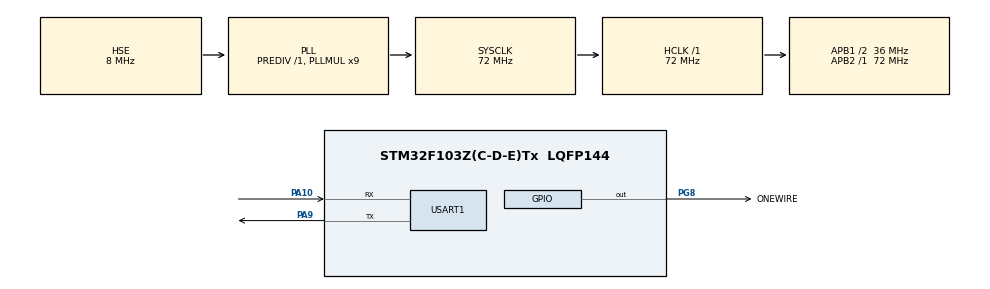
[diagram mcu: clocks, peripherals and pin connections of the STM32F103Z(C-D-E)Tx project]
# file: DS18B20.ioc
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Mcu.Family=STM32F1
Mcu.Name=STM32F103Z(C-D-E)Tx
Mcu.Package=LQFP144
NVIC.PriorityGroup=NVIC_PRIORITYGROUP_4
OSC_IN.Mode=HSE-External-Oscillator
OSC_IN.Signal=RCC_OSC_IN
OSC_OUT.Mode=HSE-External-Oscillator
OSC_OUT.Signal=RCC_OSC_OUT
PA10.Mode=Asynchronous
PA10.Signal=USART1_RX
PA9.Mode=Asynchronous
PA9.Signal=USART1_TX
PG8.GPIO_Label=ONEWIRE
PG8.Signal=GPIO_Output
ProjectManager.HeapSize=0x200
ProjectManager.StackSize=0x400
ProjectManager.TargetToolchain=MDK-ARM V5
RCC.AHBFreq_Value=72000000
RCC.APB1CLKDivider=RCC_HCLK_DIV2
RCC.APB1Freq_Value=36000000
RCC.APB1TimFreq_Value=72000000
RCC.APB2Freq_Value=72000000
RCC.APB2TimFreq_Value=72000000
RCC.HCLKFreq_Value=72000000
RCC.HSIState=RCC_HSI_ON
RCC.PLLMUL=RCC_PLL_MUL9
RCC.PLLSourceVirtual=RCC_PLLSOURCE_HSE
RCC.SYSCLKFreq_VALUE=72000000
RCC.SYSCLKSource=RCC_SYSCLKSOURCE_PLLCLK
RCC.USBFreq_Value=72000000
VP_SYS_VS_ND.Mode=No_Debug
board=DS18B20

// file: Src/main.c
/**
  ******************************************************************************
  * File Name          : main.c
  * Description        : Main program body
  ******************************************************************************
  *
  * COPYRIGHT(c) 2017 STMicroelectronics
  *
  * Redistribution and use in source and binary forms, with or without modification,
  * are permitted provided that the following conditions are met:
  *   1. Redistributions of source code must retain the above copyright notice,
  *      this list of conditions and the following disclaimer.
  *   2. Redistributions in binary form must reproduce the above copyright notice,
  *      this list of conditions and the following disclaimer in the documentation
  *      and/or other materials provided with the distribution.
  *   3. Neither the name of STMicroelectronics nor the names of its contributors
  *      may be used to endorse or promote products derived from this software
  *      without specific prior written permission.
  *
  * THIS SOFTWARE IS PROVIDED BY THE COPYRIGHT HOLDERS AND CONTRIBUTORS "AS IS"
  * AND ANY EXPRESS OR IMPLIED WARRANTIES, INCLUDING, BUT NOT LIMITED TO, THE
  * IMPLIED WARRANTIES OF MERCHANTABILITY AND FITNESS FOR A PARTICULAR PURPOSE ARE
  * DISCLAIMED. IN NO EVENT SHALL THE COPYRIGHT HOLDER OR CONTRIBUTORS BE LIABLE
  * FOR ANY DIRECT, INDIRECT, INCIDENTAL, SPECIAL, EXEMPLARY, OR CONSEQUENTIAL
  * DAMAGES (INCLUDING, BUT NOT LIMITED TO, PROCUREMENT OF SUBSTITUTE GOODS OR
  * SERVICES; LOSS OF USE, DATA, OR PROFITS; OR BUSINESS INTERRUPTION) HOWEVER
  * CAUSED AND ON ANY THEORY OF LIABILITY, WHETHER IN CONTRACT, STRICT LIABILITY,
  * OR TORT (INCLUDING NEGLIGENCE OR OTHERWISE) ARISING IN ANY WAY OUT OF THE USE
  * OF THIS SOFTWARE, EVEN IF ADVISED OF THE POSSIBILITY OF SUCH DAMAGE.
  *
  ******************************************************************************
  */
#include "main.h"
#include "stm32f1xx_hal.h"
#include "usart.h"
#include "gpio.h"

/* USER CODE BEGIN Includes */
#include "ds18b20.h"
/* USER CODE END Includes */

/* USER CODE BEGIN PV */
/* Private variables ---------------------------------------------------------*/

/* USER CODE END PV */

void SystemClock_Config(void);
void Error_Handler(void);

/* USER CODE BEGIN PFP */
/* Private function prototypes -----------------------------------------------*/

/* USER CODE END PFP */

int main(void)
{

  /* USER CODE BEGIN 1 */
  int16_t temp;
  /* USER CODE END 1 */

  /* MCU Configuration----------------------------------------------------------*/

  /* Reset of all peripherals, Initializes the Flash interface and the Systick. */
  HAL_Init();

  /* Configure the system clock */
  SystemClock_Config();

  /* Initialize all configured peripherals */
  MX_GPIO_Init();
  MX_USART1_UART_Init();

  /* USER CODE BEGIN 2 */
  printf ("DS18B20 Example\r\n");

  /* Initialize DS18B20 and chack */
  while(DS18B20_Init())
  {
    printf ("DS18B20 Check Failed! Please Check!\r\n");
    HAL_Delay(500);
  }
  temp=DS18B20_Get_Temp();
  HAL_Delay(800);
  /* USER CODE END 2 */

  /* Infinite loop */
  while (1)
  {

  /* USER CODE BEGIN 3 */
    temp = DS18B20_Get_Temp();
    printf("Temperate:  %3.1f C \r\n",temp/10.0f );
    HAL_Delay(500);
  }
  /* USER CODE END 3 */

}

/** System Clock Configuration
*/
void SystemClock_Config(void)
{

  RCC_OscInitTypeDef RCC_OscInitStruct;
  RCC_ClkInitTypeDef RCC_ClkInitStruct;

    /**Initializes the CPU, AHB and APB busses clocks
    */
  RCC_OscInitStruct.OscillatorType = RCC_OSCILLATORTYPE_HSE;
  RCC_OscInitStruct.HSEState = RCC_HSE_ON;
  RCC_OscInitStruct.HSEPredivValue = RCC_HSE_PREDIV_DIV1;
  RCC_OscInitStruct.HSIState = RCC_HSI_ON;
  RCC_OscInitStruct.PLL.PLLState = RCC_PLL_ON;
  RCC_OscInitStruct.PLL.PLLSource = RCC_PLLSOURCE_HSE;
  RCC_OscInitStruct.PLL.PLLMUL = RCC_PLL_MUL9;
  if (HAL_RCC_OscConfig(&RCC_OscInitStruct) != HAL_OK)
  {
    Error_Handler();
  }

    /**Initializes the CPU, AHB and APB busses clocks
    */
  RCC_ClkInitStruct.ClockType = RCC_CLOCKTYPE_HCLK|RCC_CLOCKTYPE_SYSCLK
                              |RCC_CLOCKTYPE_PCLK1|RCC_CLOCKTYPE_PCLK2;
  RCC_ClkInitStruct.SYSCLKSource = RCC_SYSCLKSOURCE_PLLCLK;
  RCC_ClkInitStruct.AHBCLKDivider = RCC_SYSCLK_DIV1;
  RCC_ClkInitStruct.APB1CLKDivider = RCC_HCLK_DIV2;
  RCC_ClkInitStruct.APB2CLKDivider = RCC_HCLK_DIV1;

  if (HAL_RCC_ClockConfig(&RCC_ClkInitStruct, FLASH_LATENCY_2) != HAL_OK)
  {
    Error_Handler();
  }

    /**Configure the Systick interrupt time
    */
  HAL_SYSTICK_Config(HAL_RCC_GetHCLKFreq()/1000);

    /**Configure the Systick
    */
  HAL_SYSTICK_CLKSourceConfig(SYSTICK_CLKSOURCE_HCLK);

  /* SysTick_IRQn interrupt configuration */
  HAL_NVIC_SetPriority(SysTick_IRQn, 0, 0);
}

void Error_Handler(void)
{
  while(1)
  {
  }
}

/************************ (C) COPYRIGHT STMicroelectronics *****END OF FILE****/
